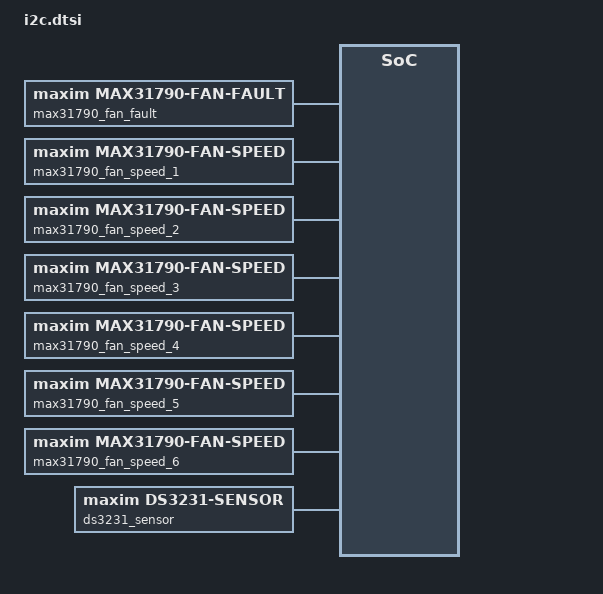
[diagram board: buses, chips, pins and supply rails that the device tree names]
/*
 * Copyright (c) 2020, Linaro Ltd.
 *
 * SPDX-License-Identifier: Apache-2.0
 *
 * Application overlay for i2c devices
 */

#include <zephyr/dt-bindings/sensor/lsm6dsv16x.h>
#include <zephyr/dt-bindings/sensor/lsm6dso.h>
#include <zephyr/dt-bindings/sensor/lsm6dso16is.h>
#include <zephyr/dt-bindings/sensor/lps22hh.h>
#include <zephyr/dt-bindings/sensor/lps2xdf.h>
#include <zephyr/dt-bindings/sensor/lis2ds12.h>
#include <zephyr/dt-bindings/sensor/lis2dw12.h>
#include <zephyr/dt-bindings/sensor/ism330dhcx.h>
#include <zephyr/dt-bindings/sensor/iis2dlpc.h>
#include <zephyr/dt-bindings/sensor/lis2dh.h>
#include <zephyr/dt-bindings/sensor/iis2iclx.h>
#include <zephyr/dt-bindings/sensor/lis2du12.h>
#include <zephyr/dt-bindings/sensor/lis2dux12.h>
#include <zephyr/dt-bindings/sensor/lis2de12.h>
#include <zephyr/dt-bindings/sensor/tmag5273.h>
#include <zephyr/dt-bindings/sensor/stts22h.h>
#include <zephyr/dt-bindings/sensor/ina226.h>
#include <zephyr/dt-bindings/sensor/apds9253.h>
#include <zephyr/dt-bindings/sensor/tmp11x.h>
#include <zephyr/dt-bindings/sensor/tmp114.h>

#define TEST_I2C_DEVICE_WITH_ADDR(label, node, addr, ...) \
	label: node@addr { \
		reg = <addr>; \
		__VA_ARGS__ \
	}

#define TEST_I2C_DEVICE(sensor, ...) \
	TEST_I2C_DEVICE_WITH_ADDR(test_i2c_##sensor, sensor, __COUNTER__, __VA_ARGS__)


TEST_I2C_DEVICE(adt7420,
	compatible = "adi,adt7420";
	int-gpios = <&test_gpio 0 0>;
);

TEST_I2C_DEVICE(adxl345,
	compatible = "adi,adxl345";
	int1-gpios = <&test_gpio 0 0>;
	fifo-watermark = <1>;
);

TEST_I2C_DEVICE(adxl372,
	compatible = "adi,adxl372";
	int1-gpios = <&test_gpio 0 0>;
);

TEST_I2C_DEVICE(ccs811,
	compatible = "ams,ccs811";
	wake-gpios = <&test_gpio 0 0>;
	reset-gpios = <&test_gpio 0 0>;
	irq-gpios = <&test_gpio 0 0>;
);

TEST_I2C_DEVICE(ens210,
	compatible = "ams,ens210";
);

TEST_I2C_DEVICE(iaqcore,
	compatible = "ams,iaqcore";
);

TEST_I2C_DEVICE(bme280,
	compatible = "bosch,bme280";
);

TEST_I2C_DEVICE(apds9960,
	compatible = "avago,apds9960";
	int-gpios = <&test_gpio 0 0>;
);

TEST_I2C_DEVICE(bma280,
	compatible = "bosch,bma280";
	int1-gpios = <&test_gpio 0 0>;
	/* is-bmc150; */
);

TEST_I2C_DEVICE(bmc150_magn,
	compatible = "bosch,bmc150_magn";
	drdy-gpios = <&test_gpio 0 0>;
);

TEST_I2C_DEVICE(ak8975,
	compatible = "asahi-kasei,ak8975";
);

TEST_I2C_DEVICE(bme680,
	compatible = "bosch,bme680";
);

TEST_I2C_DEVICE(bmg160,
	compatible = "bosch,bmg160";
	int-gpios = <&test_gpio 0 0>;
);

TEST_I2C_DEVICE(bmm150,
	compatible = "bosch,bmm150";
	drdy-gpios = <&test_gpio 0 0>;
);

TEST_I2C_DEVICE(hmc5883l,
	compatible = "honeywell,hmc5883l";
	int-gpios = <&test_gpio 0 0>;
);

TEST_I2C_DEVICE(hp206c,
	compatible = "hoperf,hp206c";
);

TEST_I2C_DEVICE(th02,
	compatible = "hoperf,th02";
);

TEST_I2C_DEVICE(mpu6050,
	compatible = "invensense,mpu6050";
	int-gpios = <&test_gpio 0 0>;
);

TEST_I2C_DEVICE(mpu9250,
	compatible = "invensense,mpu9250";
	irq-gpios = <&test_gpio 0 0>;
	gyro-sr-div = <10>;
	gyro-dlpf = <5>;
	gyro-fs = <250>;
	accel-fs = <2>;
	accel-dlpf = "5.05";
);

TEST_I2C_DEVICE(ina219,
	compatible = "ti,ina219";
	brng = <0>;
	pg = <0>;
	sadc = <13>;
	badc = <13>;
	shunt-milliohm = <100>;
	lsb-microamp = <10>;
);

TEST_I2C_DEVICE(isl29035,
	compatible = "isil,isl29035";
	int-gpios = <&test_gpio 0 0>;
);

TEST_I2C_DEVICE(max30101,
	compatible = "maxim,max30101";
	acq-mode = "multi-led";
);

TEST_I2C_DEVICE(max44009,
	compatible = "maxim,max44009";
	int-gpios = <&test_gpio 0 0>;
);

TEST_I2C_DEVICE(ms5607,
	compatible = "meas,ms5607";
);

TEST_I2C_DEVICE(ms5837_02ba,
	compatible = "meas,ms5837-02ba";
	status = "okay";
);

TEST_I2C_DEVICE(jc42,
	compatible = "jedec,jc-42.4-temp";
	int-gpios = <&test_gpio 0 0>;
);

TEST_I2C_DEVICE(fxas21002,
	compatible = "nxp,fxas21002";
	int1-gpios = <&test_gpio 0 0>;
	int2-gpios = <&test_gpio 0 0>;
);

TEST_I2C_DEVICE(fxos8700,
	compatible = "nxp,fxos8700";
	reset-gpios = <&test_gpio 0 0>;
	int1-gpios = <&test_gpio 0 0>;
	int2-gpios = <&test_gpio 0 0>;
);

TEST_I2C_DEVICE(amg88xx,
	compatible = "panasonic,amg88xx";
	int-gpios = <&test_gpio 0 0>;
);

TEST_I2C_DEVICE(sx9500,
	compatible = "semtech,sx9500";
	int-gpios = <&test_gpio 0 0>;
);

TEST_I2C_DEVICE(sgp40,
	compatible = "sensirion,sgp40";
	enable-selftest;
);

TEST_I2C_DEVICE(sht3xd,
	compatible = "sensirion,sht3xd";
	alert-gpios = <&test_gpio 0 0>;
);

TEST_I2C_DEVICE(sht4xd,
	compatible = "sensirion,sht4x";
	repeatability = <2>;
);

TEST_I2C_DEVICE(shtc3,
	compatible = "sensirion,shtc3", "sensirion,shtcx";
	measure-mode = "normal";
	clock-stretching;
);

TEST_I2C_DEVICE(si7006,
	compatible = "silabs,si7006";
);

TEST_I2C_DEVICE(si7055,
	compatible = "silabs,si7055";
);

TEST_I2C_DEVICE(si7060,
	compatible = "silabs,si7060";
);

TEST_I2C_DEVICE(si7210,
	compatible = "silabs,si7210";
);

TEST_I2C_DEVICE(hts221,
	compatible = "st,hts221";
	drdy-gpios = <&test_gpio 0 0>;
);

TEST_I2C_DEVICE(iis2dlpc,
	compatible = "st,iis2dlpc";
	drdy-gpios = <&test_gpio 0 0>;
	tap-mode = <IIS2DLPC_DT_SINGLE_DOUBLE_TAP>;
	power-mode = <IIS2DLPC_DT_HP_MODE>;
);

TEST_I2C_DEVICE(iis2mdc,
	compatible = "st,iis2mdc";
	drdy-gpios = <&test_gpio 0 0>;
);

TEST_I2C_DEVICE(ism330dhcx,
	compatible = "st,ism330dhcx";
	drdy-gpios = <&test_gpio 0 0>;
	accel-odr = <ISM330DHCX_DT_ODR_104Hz>;
	gyro-odr = <ISM330DHCX_DT_ODR_104Hz>;
);

TEST_I2C_DEVICE(lis2dh,
	compatible = "st,lis2dh";
	irq-gpios = <&test_gpio 0 0>;
	/* disconnect-sdo-sa0-pull-up; */
	int1-gpio-config = <LIS2DH_DT_GPIO_INT_LEVEL_LOW>;
	int2-gpio-config = <LIS2DH_DT_GPIO_INT_LEVEL_LOW>;
	anym-mode = <LIS2DH_DT_ANYM_6D_POSITION>;
);

TEST_I2C_DEVICE(lis2dh12,
	compatible = "st,lis2dh12";
	irq-gpios = <&test_gpio 0 0>;
	status = "disabled";
);

TEST_I2C_DEVICE(lis2ds12,
	compatible = "st,lis2ds12";
	irq-gpios = <&test_gpio 0 0>;
	power-mode = <LIS2DS12_DT_LOW_POWER>;
	odr = <LIS2DS12_DT_ODR_12Hz5>;
);

TEST_I2C_DEVICE(lis2dw12,
	compatible = "st,lis2dw12";
	irq-gpios = <&test_gpio 0 0>;
	wakeup-duration = <LIS2DW12_DT_WAKEUP_4_ODR>;
	ff-threshold = <LIS2DW12_DT_FF_THRESHOLD_500_mg>;
	tap-mode = <LIS2DW12_DT_SINGLE_DOUBLE_TAP>;
	power-mode = <LIS2DW12_DT_HP_MODE>;
	bw-filt = <LIS2DW12_DT_FILTER_BW_ODR_DIV_2>;
);

TEST_I2C_DEVICE(lis2mdl,
	compatible = "st,lis2mdl";
	irq-gpios = <&test_gpio 0 0>;
);

TEST_I2C_DEVICE(lis3dh,
	compatible = "st,lis3dh";
	irq-gpios = <&test_gpio 0 0>;
	status = "disabled";
);

TEST_I2C_DEVICE(lis3mdl_magn,
	compatible = "st,lis3mdl-magn";
	irq-gpios = <&test_gpio 0 0>;
);

TEST_I2C_DEVICE(lps22hb_press,
	compatible = "st,lps22hb-press";
);

TEST_I2C_DEVICE(lps22hh,
	compatible = "st,lps22hh";
	drdy-gpios = <&test_gpio 0 0>;
	odr = <LPS22HH_DT_ODR_200HZ>;
);

TEST_I2C_DEVICE(lps25hb_press,
	compatible = "st,lps25hb-press";
);

TEST_I2C_DEVICE(lsm303agr_accel,
	compatible = "st,lsm303agr-accel";
	irq-gpios = <&test_gpio 0 0>;
	/* disconnect-sdo-sa0-pull-up; */
	status = "disabled";
);

TEST_I2C_DEVICE(lsm303dlhc_accel,
	compatible = "st,lsm303dlhc-accel";
	irq-gpios = <&test_gpio 0 0>;
	/* disconnect-sdo-sa0-pull-up; */
	status = "disabled";
);

TEST_I2C_DEVICE(lsm303dlhc_magn,
	compatible = "st,lsm303dlhc-magn";
);

TEST_I2C_DEVICE(lsm6ds0,
	compatible = "st,lsm6ds0";
);

TEST_I2C_DEVICE(lsm6dsl,
	compatible = "st,lsm6dsl";
	irq-gpios = <&test_gpio 0 0>;
);

TEST_I2C_DEVICE(lsm6dso,
	compatible = "st,lsm6dso";
	irq-gpios = <&test_gpio 0 0>;
	accel-pm = <LSM6DSO_DT_XL_ULP_MODE>;
	accel-range = <LSM6DSO_DT_FS_8G>;
	accel-odr = <LSM6DSO_DT_ODR_1Hz6>;
	gyro-pm = <LSM6DSO_DT_GY_NORMAL_MODE>;
	gyro-range = <LSM6DSO_DT_FS_2000DPS>;
	gyro-odr = <LSM6DSO_DT_ODR_6667Hz>;
);

TEST_I2C_DEVICE(lsm9ds0_gyro,
	compatible = "st,lsm9ds0-gyro";
	irq-gpios = <&test_gpio 0 0>;
);

TEST_I2C_DEVICE(lsm9ds0_mfd,
	compatible = "st,lsm9ds0-mfd";
	irq-gpios = <&test_gpio 0 0>;
);

TEST_I2C_DEVICE(stts751,
	compatible = "st,stts751";
	drdy-gpios = <&test_gpio 0 0>;
);

TEST_I2C_DEVICE(vl53l0x,
	compatible = "st,vl53l0x";
	xshut-gpios = <&test_gpio 0 0>;
);

TEST_I2C_DEVICE(hdc,
	compatible = "ti,hdc";
	drdy-gpios = <&test_gpio 0 0>;
);

TEST_I2C_DEVICE(hdc2010,
	compatible = "ti,hdc2010";
);

TEST_I2C_DEVICE(hdc2021,
	compatible = "ti,hdc2021";
);

TEST_I2C_DEVICE(hdc2022,
	compatible = "ti,hdc2022";
);

TEST_I2C_DEVICE(hdc2080,
	compatible = "ti,hdc2080";
);

TEST_I2C_DEVICE(opt3001,
	compatible = "ti,opt3001";
);

TEST_I2C_DEVICE(tmp007,
	compatible = "ti,tmp007";
	int-gpios = <&test_gpio 0 0>;
);

TEST_I2C_DEVICE(tmp108,
	compatible = "ti,tmp108";
	alert-gpios = <&test_gpio 0 0>;
);

TEST_I2C_DEVICE(tmp112,
	compatible = "ti,tmp112";
);

TEST_I2C_DEVICE(tmp11x,
	compatible = "ti,tmp11x";
	odr = <TMP11X_DT_ODR_125_MS>;
	oversampling = <TMP11X_DT_OVERSAMPLING_32>;
	alert-gpios = <&test_gpio 0 0>;
);

TEST_I2C_DEVICE(bq274xx,
	compatible = "ti,bq274xx";
	design-voltage = <3700>;
	design-capacity = <1800>;
	taper-current = <45>;
	terminate-voltage = <3000>;
	int-gpios = <&test_gpio 0 0>;
);

TEST_I2C_DEVICE(mpr,
	compatible = "honeywell,mpr";
);

TEST_I2C_DEVICE(dps310,
	compatible = "infineon,dps310";
);

TEST_I2C_DEVICE(iis2dh,
	compatible = "st,iis2dh";
	drdy-gpios = <&test_gpio 0 0>;
);

TEST_I2C_DEVICE(iis2iclx,
	compatible = "st,iis2iclx";
	drdy-gpios = <&test_gpio 0 0>;
	int-pin = <1>;
	range = <IIS2ICLX_DT_FS_2G>;
	odr = <IIS2ICLX_DT_ODR_833Hz>;
);

TEST_I2C_DEVICE(itds_2533020201601,
	compatible = "we,wsen-itds-2533020201601";
	events-interrupt-gpios = <&test_gpio 0 0>;
	drdy-interrupt-gpios = <&test_gpio 0 0>;
	odr = "400";
	tap-threshold = <0>, <0>, <6>;
	tap-latency = <5>;
	tap-shock = <2>;
	tap-quiet = <1>;
	tap-mode = <1>;
	freefall-duration = <6>;
	freefall-threshold = <10>;
	delta-duration = <1>;
	delta-threshold = <4>;
	op-mode = "high-perf";
	power-mode = "normal";
);

TEST_I2C_DEVICE(max17055,
	compatible = "maxim,max17055";
	design-capacity = <1500>;
	design-voltage = <3860>;
	desired-charging-current = <2000>;
	desired-voltage = <4400>;
	i-chg-term = <100>;
	rsense-mohms = <5>;
	v-empty = <3300>;
);

TEST_I2C_DEVICE(max17262,
	compatible = "maxim,max17262";
	design-voltage = <3600>;
	desired-voltage = <3600>;
	desired-charging-current = <2000>;
	design-cap = <17000>;
	empty-voltage = <3300>;
	recovery-voltage = <3880>;
	charge-voltage = <3600>;
);

TEST_I2C_DEVICE(vcnl4040,
	compatible = "vishay,vcnl4040";
	int-gpios = <&test_gpio 0 0>;
);

TEST_I2C_DEVICE(bmi160,
	compatible = "bosch,bmi160";
	int-gpios = <&test_gpio 0 0>;
);

TEST_I2C_DEVICE(bmi270,
	compatible = "bosch,bmi270";
	irq-gpios = <&test_gpio 0 0>;
);

TEST_I2C_DEVICE(fdc2x1x,
	compatible = "ti,fdc2x1x";
	intb-gpios = <&test_gpio 0 0>;
	sd-gpios = <&test_gpio 0 0>;
	deglitch = <5>;
	fref = <43360>;
	channel_0 {
		rcount = <7499>;
		settlecount = <48>;
		fref-divider = <1>;
		idrive = <10>;
		fin-sel = <2>;
		inductance = <18>;
	};
);

TEST_I2C_DEVICE(bmp388,
	compatible = "bosch,bmp388";
	int-gpios = <&test_gpio 0 0>;
);

TEST_I2C_DEVICE(lm75,
	compatible = "lm75";
	int-gpios = <&test_gpio 0 0>;
);

TEST_I2C_DEVICE(ina230,
	compatible = "ti,ina230";
	current-lsb-microamps = <1000>;
	rshunt-micro-ohms = <1000>;
	mask = <0>;
	alert-limit = <0>;
	alert-gpios = <&test_gpio 0 0>;
);

TEST_I2C_DEVICE(lm77,
	compatible = "lm77";
	int-gpios = <&test_gpio 0 0>;
);

TEST_I2C_DEVICE(ina231,
	compatible = "ti,ina230";
	current-lsb-microamps = <1000>;
	rshunt-micro-ohms = <1000>;
	mask = <0>;
	alert-limit = <0>;
	alert-gpios = <&test_gpio 0 0>;
);

TEST_I2C_DEVICE(ina237,
	compatible = "ti,ina237";
	current-lsb-microamps = <1000>;
	rshunt-micro-ohms = <1000>;
	alert-config = <0>;
	alert-gpios = <&test_gpio 0 0>;
);

TEST_I2C_DEVICE(max31875,
	compatible = "maxim,max31875";
);

TEST_I2C_DEVICE(icp101xx,
	compatible = "invensense,icp101xx";
	mode = "normal";
);

TEST_I2C_DEVICE(as5600,
	compatible = "ams,as5600";
);

TEST_I2C_DEVICE(bh1750,
	compatible = "rohm,bh1750";
);

TEST_I2C_DEVICE(akm09918c,
	compatible = "asahi-kasei,akm09918c";
);

TEST_I2C_DEVICE(wsen_tids_2521020222501,
	compatible = "we,wsen-tids-2521020222501";
	interrupt-gpios = <&test_gpio 0 0>;
	odr = <25>;
);

TEST_I2C_DEVICE(vl53l1x,
	compatible = "st,vl53l1x";
	int-gpios = <&test_gpio 0 0>;
	xshut-gpios = <&test_gpio 0 0>;
);

TEST_I2C_DEVICE(tmd2620,
	compatible = "ams,tmd2620";
	int-gpios = <&test_gpio 0 0>;
	proximity-gain = <4>;
	proximity-pulse-length = <16>;
	proximity-pulse-count = <15>;
	proximity-high-threshold = <255>;
	proximity-low-threshold = <0>;
	proximity-led-drive-strength = <4>;
	proximity-interrupt-filter = <0>;
	wait-time-factor = <0>;
);

TEST_I2C_DEVICE(wsen_pads_2511020213301,
	compatible = "we,wsen-pads-2511020213301";
	interrupt-gpios = <&test_gpio 0 0>;
	odr = <10>;
);

TEST_I2C_DEVICE(s11059,
	compatible = "hamamatsu,s11059";
	integration-time = <546000>;
);

TEST_I2C_DEVICE(wsen_pdus_25131308XXXXX,
	compatible = "we,wsen-pdus-25131308XXXXX";
	sensor-type = <4>;
);

TEST_I2C_DEVICE(veml7700,
	compatible = "vishay,veml7700";
	psm-mode = <0x03>;
);

TEST_I2C_DEVICE(ina3221,
	compatible = "ti,ina3221";
	shunt-resistors = <1000 1000 1000>;
	enable-channel = <1 0 0>;
	conv-time-bus = <7>;
	conv-time-shunt = <7>;
	avg-mode = <2>;
);

TEST_I2C_DEVICE(lsm6dso16is,
	compatible = "st,lsm6dso16is";
	irq-gpios = <&test_gpio 0 0>;
	accel-range = <LSM6DSO16IS_DT_FS_8G>;
	accel-odr = <LSM6DSO16IS_DT_ODR_104Hz_LP>;
	gyro-range = <LSM6DSO16IS_DT_FS_2000DPS>;
	gyro-odr = <LSM6DSO16IS_DT_ODR_104Hz_LP>;
);

TEST_I2C_DEVICE(lsm6dsv16x,
	compatible = "st,lsm6dsv16x";
	int1-gpios = <&test_gpio 0 0>;
	int2-gpios = <&test_gpio 0 0>;
	accel-range = <LSM6DSV16X_DT_FS_8G>;
	accel-odr = <LSM6DSV16X_DT_ODR_AT_60Hz>;
	gyro-range = <LSM6DSV16X_DT_FS_2000DPS>;
	gyro-odr = <LSM6DSV16X_DT_ODR_AT_60Hz>;
);

TEST_I2C_DEVICE(mcp9600,
	compatible = "microchip,mcp9600";
);

TEST_I2C_DEVICE(tcs3400,
	compatible = "ams,tcs3400";
	int-gpios = <&test_gpio 0 0>;
);

TEST_I2C_DEVICE(tcn75a,
	compatible = "microchip,tcn75a";
	alert-gpios = <&test_gpio 0 0>;
);

TEST_I2C_DEVICE(bmi08x_accel,
	compatible = "bosch,bmi08x-accel";
	int-gpios = <&test_gpio 0 0>;
	int1-map-io = <0x01>;
	int2-map-io = <0x00>;
	int1-conf-io = <0x0A>;
	int2-conf-io = <0x17>;
	accel-hz = "800";
	accel-fs = <4>;
	fifo-watermark = <1>;
);

TEST_I2C_DEVICE(bmi08x_gyro,
	compatible = "bosch,bmi08x-gyro";
	int-gpios = <&test_gpio 0 0>;
	int3-4-map-io = <0x01>;
	int3-4-conf-io = <0x01>;
	gyro-hz = "1000_116";
	gyro-fs = <1000>;
	fifo-watermark = <1>;
);

TEST_I2C_DEVICE(ist8310,
	compatible = "isentek,ist8310";
	status = "okay";
);

TEST_I2C_DEVICE(f75303,
	compatible = "fintek,f75303";
);

TEST_I2C_DEVICE(tsl2540,
	compatible = "ams,tsl2540";
	int-gpios = <&test_gpio 0 0>;
);

TEST_I2C_DEVICE(adltc2990,
	compatible = "adi,adltc2990";
	status = "okay";
	measurement-mode = <7 3>;
	pins-v1-v2-current-resistor = <1>;
	pin-v1-voltage-divider-resistors = <100 10>;
	pin-v2-voltage-divider-resistors = <100 10>;
	pin-v3-voltage-divider-resistors = <100 100>;
	pin-v4-voltage-divider-resistors = <0 1>;
);

TEST_I2C_DEVICE(hm330x,
	compatible = "seeed,hm330x";
	status = "okay";
);

TEST_I2C_DEVICE(amd_sb_tsi,
	compatible = "amd,sb-tsi";
);

TEST_I2C_DEVICE(mc3419,
	compatible = "memsic,mc3419";
	int-gpios = <&test_gpio 0 0>;
);

TEST_I2C_DEVICE(ltrf216a0,
	compatible = "liteon,ltrf216a";
);

TEST_I2C_DEVICE(adxl367,
	compatible = "adi,adxl367";
	odr = <4>;
	int1-gpios = <&test_gpio 0 0>;
);

TEST_I2C_DEVICE(tsl2561,
	compatible = "ams,tsl2561";
);

TEST_I2C_DEVICE(lps22df,
	compatible = "st,lps22df";
	drdy-gpios = <&test_gpio 0 0>;
	status = "okay";
	odr = <LPS2xDF_DT_ODR_10HZ>;
	lpf = <LPS2xDF_DT_LP_FILTER_ODR_4>;
	avg = <LPS2xDF_DT_AVG_128_SAMPLES>;
);

TEST_I2C_DEVICE(hs300x,
	compatible = "renesas,hs300x";
);

TEST_I2C_DEVICE(lps28dfw,
	compatible = "st,lps28dfw";
	drdy-gpios = <&test_gpio 0 0>;
	status = "okay";
	odr = <LPS2xDF_DT_ODR_10HZ>;
	lpf = <LPS2xDF_DT_LP_FILTER_ODR_4>;
	avg = <LPS2xDF_DT_AVG_128_SAMPLES>;
	fs = <LPS28DFW_DT_FS_MODE_1_1260>;
);

TEST_I2C_DEVICE(lis2du12,
	compatible = "st,lis2du12";
	int1-gpios = <&test_gpio 0 0>;
	int2-gpios = <&test_gpio 0 0>;
	accel-range = <LIS2DU12_DT_FS_16G>;
	accel-odr = <LIS2DU12_DT_ODR_AT_800Hz>;
);

TEST_I2C_DEVICE(bma4xx,
	compatible = "bosch,bma4xx";
);

TEST_I2C_DEVICE(ags10,
	compatible = "aosong,ags10";
);

TEST_I2C_DEVICE(bmp581,
	compatible = "bosch,bmp581";
	int-gpios = <&test_gpio 0 0>;
);

TEST_I2C_DEVICE(lis2de12,
	compatible = "st,lis2de12";
	int1-gpios = <&test_gpio 0 0>;
	int2-gpios = <&test_gpio 0 0>;
	accel-range = <LIS2DE12_DT_FS_16G>;
	accel-odr = <LIS2DE12_DT_ODR_AT_100Hz>;
);

TEST_I2C_DEVICE(vishay_vcnl36825t,
	compatible = "vishay,vcnl36825t";

	proximity-it = "1";
	multi-pulse = <8>;

	low-power;

	int-gpios = <&test_gpio 0 0>;
);

TEST_I2C_DEVICE(tmag5273,
	compatible = "ti,tmag5273";
	status = "okay";
	int-gpios = <&test_gpio 15 1>;

	operation-mode = <TMAG5273_DT_OPER_MODE_CONTINUOUS>;
	angle-magnitude-axis = <TMAG5273_DT_ANGLE_MAG_XY>;
);

TEST_I2C_DEVICE(ens160,
	compatible = "sciosense,ens160";
	int-gpios = <&test_gpio 0 0>;
);

TEST_I2C_DEVICE(tsl2591,
	compatible = "ams,tsl2591";
	int-gpios = <&test_gpio 0 0>;
);

TEST_I2C_DEVICE(max31790,
	compatible = "maxim,max31790";
	status = "okay";

	max31790_fan_fault: max31790_fan_fault {
		compatible = "maxim,max31790-fan-fault";
		status = "okay";
	};

	max31790_fan_speed_1: max31790_fan_speed_1 {
		compatible = "maxim,max31790-fan-speed";
		status = "okay";
		channel = <1>;
	};

	max31790_fan_speed_2: max31790_fan_speed_2 {
		compatible = "maxim,max31790-fan-speed";
		status = "okay";
		channel = <2>;
	};

	max31790_fan_speed_3: max31790_fan_speed_3 {
		compatible = "maxim,max31790-fan-speed";
		status = "okay";
		channel = <3>;
	};

	max31790_fan_speed_4: max31790_fan_speed_4 {
		compatible = "maxim,max31790-fan-speed";
		status = "okay";
		channel = <4>;
	};

	max31790_fan_speed_5: max31790_fan_speed_5 {
		compatible = "maxim,max31790-fan-speed";
		status = "okay";
		channel = <5>;
	};

	max31790_fan_speed_6: max31790_fan_speed_6 {
		compatible = "maxim,max31790-fan-speed";
		status = "okay";
		channel = <6>;
	};
);

TEST_I2C_DEVICE(stts22h,
	compatible = "st,stts22h";
	int-gpios = <&test_gpio 0 0>;
	sampling-rate = <STTS22H_100Hz>;
);

TEST_I2C_DEVICE(dht20,
	compatible = "aosong,dht20";
	status = "okay";
);

TEST_I2C_DEVICE(aht20,
	compatible = "aosong,aht20";
	status = "okay";
);

TEST_I2C_DEVICE(am2301b,
	compatible = "aosong,am2301b";
);

TEST_I2C_DEVICE(lis2dux12,
	compatible = "st,lis2dux12";
	int1-gpios = <&test_gpio 0 0>;
	int2-gpios = <&test_gpio 0 0>;
	range = <LIS2DUX12_DT_FS_16G>;
	odr = <LIS2DUX12_DT_ODR_100Hz>;
	power-mode = <LIS2DUX12_OPER_MODE_HIGH_PERFORMANCE>;
	status = "okay";
);

TEST_I2C_DEVICE(iis328dq,
	compatible = "st,iis328dq";
	status = "okay";
	int2-gpios = <&test_gpio 0 0>;
	threshold-int-pad = <2>;
);

TEST_I2C_DEVICE(nct75,
	compatible = "onnn,nct75";
	status = "okay";
);

TEST_I2C_DEVICE(tmp114,
	compatible = "ti,tmp114";
	odr = <TMP114_DT_ODR_250_MS>;
);

TEST_I2C_DEVICE(ina226,
	compatible = "ti,ina226";
	current-lsb-microamps = <5000>;
	rshunt-micro-ohms = <500>;
);

TEST_I2C_DEVICE(shtc1,
	compatible = "sensirion,shtc1", "sensirion,shtcx";
	measure-mode = "low-power";
	clock-stretching;
);

TEST_I2C_DEVICE(lm95234,
	compatible = "national,lm95234";
	status = "okay";
);

TEST_I2C_DEVICE(sht21,
	compatible = "sensirion,sht21";
);

TEST_I2C_DEVICE(lsm9ds1,
	compatible = "st,lsm9ds1";
);

TEST_I2C_DEVICE(icm42670p,
	compatible = "invensense,icm42670p";
	int-gpios = <&test_gpio 0 0>;
	accel-hz = <800>;
	accel-fs = <16>;
	gyro-hz = <800>;
	gyro-fs = <2000>;
);

TEST_I2C_DEVICE(fxls8974,
	compatible = "nxp,fxls8974";
	reset-gpios = <&test_gpio 0 0>;
	int1-gpios = <&test_gpio 0 0>;
	int2-gpios = <&test_gpio 0 0>;
);

TEST_I2C_DEVICE(bmp180,
	compatible = "bosch,bmp180";
	osr-press = <0x01>;
);

TEST_I2C_DEVICE(apds9253,
	compatible = "avago,apds9253";
	int-gpios = <&test_gpio 0 0>;
	gain = <APDS9253_GAIN_RANGE_1>;
	rate = <APDS9253_MEASUREMENT_RATE_50MS>;
	resolution = <APDS9253_RESOLUTION_16BIT_25MS>;
);

TEST_I2C_DEVICE(mmc56x3,
	compatible = "memsic,mmc56x3";
	magn-odr = <0>;
	auto-self-reset;
);

TEST_I2C_DEVICE(tmp1075,
	compatible = "ti,tmp1075";
	alert-gpios = <&test_gpio 0 0>;
	conversion-rate = <220000>;
	lower-threshold = <27>;
	upper-threshold = <28>;
	consecutive-fault-measurements = <4>;
	interrupt-mode;
);

TEST_I2C_DEVICE(bmp390,
	compatible = "bosch,bmp390";
	int-gpios = <&test_gpio 0 0>;
	osr-press = <0x01>;
	odr = "12.5";
	osr-press = <8>;
	osr-temp = <1>;
	iir-filter = <3>;
);

TEST_I2C_DEVICE(apds9306,
	compatible = "avago,apds9306";
	status = "okay";
	gain = <1>;
	resolution = <13>;
	measurement-period = <2000>;
);

TEST_I2C_DEVICE(wsen_hids_2525020210002,
	compatible = "we,wsen-hids-2525020210002";
	precision = "high";
);

TEST_I2C_DEVICE(ilps22qs,
	compatible = "st,ilps22qs";
	status = "okay";
	odr = <LPS2xDF_DT_ODR_10HZ>;
	lpf = <LPS2xDF_DT_LP_FILTER_ODR_4>;
	avg = <LPS2xDF_DT_AVG_128_SAMPLES>;
	fs = <ILPS22QS_DT_FS_MODE_1_1260>;
);

TEST_I2C_DEVICE(sts4x,
	compatible = "sensirion,sts4x";
	repeatability = <2>;
);

TEST_I2C_DEVICE(scd41,
	compatible = "sensirion,scd41";
	mode = <0>;
);

TEST_I2C_DEVICE(npm2100,
	compatible = "nordic,npm2100";

	vbat {
		compatible = "nordic,npm2100-vbat";
	};
);

TEST_I2C_DEVICE(mlx90394,
	compatible = "melexis,mlx90394";
	status = "okay";
);

TEST_I2C_DEVICE(scd40,
	compatible = "sensirion,scd40";
);

TEST_I2C_DEVICE(ina236,
	compatible = "ti,ina236";
	current-lsb-microamps = <1000>;
	rshunt-micro-ohms = <1000>;
	mask = <0>;
	alert-limit = <0>;
	alert-gpios = <&test_gpio 0 0>;
);

TEST_I2C_DEVICE(as6212,
	compatible = "ams,as6212";
);

TEST_I2C_DEVICE(p3t1755,
	compatible = "nxp,p3t1755";
);

TEST_I2C_DEVICE(lsm6dso32,
	compatible = "st,lsm6dso32";
	irq-gpios = <&test_gpio 0 0>;
	accel-pm = <LSM6DSO_DT_XL_ULP_MODE>;
	accel-range = <LSM6DSO_DT_FS_8G>;
	accel-odr = <LSM6DSO_DT_ODR_1Hz6>;
	gyro-pm = <LSM6DSO_DT_GY_NORMAL_MODE>;
	gyro-range = <LSM6DSO_DT_FS_2000DPS>;
	gyro-odr = <LSM6DSO_DT_ODR_6667Hz>;
);

TEST_I2C_DEVICE(hs400x,
	compatible = "renesas,hs400x";
);

TEST_I2C_DEVICE(lis2duxs12,
	compatible = "st,lis2duxs12";
	int1-gpios = <&test_gpio 0 0>;
	int2-gpios = <&test_gpio 0 0>;
	range = <LIS2DUX12_DT_FS_16G>;
	odr = <LIS2DUX12_DT_ODR_100Hz>;
	power-mode = <LIS2DUX12_OPER_MODE_HIGH_PERFORMANCE>;
	status = "okay";
);

TEST_I2C_DEVICE(tmag3001,
	compatible = "ti,tmag3001";
	status = "okay";
	int-gpios = <&test_gpio 15 1>;
	operation-mode = <TMAG5273_DT_OPER_MODE_CONTINUOUS>;
	angle-magnitude-axis = <TMAG5273_DT_ANGLE_MAG_XY>;
);

TEST_I2C_DEVICE(tmp435,
	compatible = "ti,tmp435";
	external-channel;
	resistance-correction;
	beta-compensation = <0x0f>;
);

TEST_I2C_DEVICE(xbr818,
	compatible = "phosense,xbr818";
	int-gpios = <&test_gpio 0 0>;
	i2c-en-gpios = <&test_gpio 0 0>;
);

TEST_I2C_DEVICE(veml6031,
	compatible = "vishay,veml6031";
);

TEST_I2C_DEVICE(bmm350,
	compatible = "bosch,bmm350";
	drdy-gpios = <&test_gpio 0 0>;
);

TEST_I2C_DEVICE(ltr329,
	compatible = "liteon,ltr329";
);

TEST_I2C_DEVICE(ms5837_30ba,
	compatible = "meas,ms5837-30ba";
	status = "okay";
);

TEST_I2C_DEVICE(icp201xx,
	compatible = "invensense,icp201xx";
	int-gpios = <&test_gpio 0 0>;
	op-mode = "mode0";
	drive-strength = "current_12mA_1_8V";
);

TEST_I2C_DEVICE(paj7620,
	compatible = "pixart,paj7620";
	int-gpios = <&test_gpio 0 0>;
);

TEST_I2C_DEVICE(icm45686,
	compatible = "invensense,icm45686";
	int-gpios = <&test_gpio 0 0>;
);

TEST_I2C_DEVICE(rm3100,
	compatible = "pni,rm3100";
	int-gpios = <&test_gpio 0 0>;
);

TEST_I2C_DEVICE(bh1790,
	compatible = "rohm,bh1790";
);

TEST_I2C_DEVICE(bh1730,
	compatible = "rohm,bh1730";
);

TEST_I2C_DEVICE(npm1300,
	compatible = "nordic,npm1300";

	charger {
		compatible = "nordic,npm1300-charger";
		vbus-limit-microamp = <1000000>;
		thermistor-ohms = <10000>;
		thermistor-beta = <3380>;
		term-microvolt = <4150000>;
		current-microamp = <150000>;
		dischg-limit-microamp = <1000000>;
	};
);

TEST_I2C_DEVICE(npm1304,
	compatible = "nordic,npm1304";

	charger {
		compatible = "nordic,npm1304-charger";
		vbus-limit-microamp = <1000000>;
		thermistor-ohms = <10000>;
		thermistor-beta = <3380>;
		term-microvolt = <4150000>;
		current-microamp = <10000>;
	};
);

TEST_I2C_DEVICE(ds3231,
	compatible = "maxim,ds3231-mfd";

	test_i2c_ds3231_sensor: ds3231_sensor {
		compatible = "maxim,ds3231-sensor";
	};
);

TEST_I2C_DEVICE(adxl366,
	compatible = "adi,adxl366";
	int1-gpios = <&test_gpio 0 0>;
	odr = <4>;
	fifo-mode = <0>;
);

TEST_I2C_DEVICE(lsm9ds1_mag,
	compatible = "st,lsm9ds1_mag";
);

TEST_I2C_DEVICE(mb7040,
	compatible = "maxbotix,mb7040";
	status-gpios = <&test_gpio 0 0>;
);

TEST_I2C_DEVICE(wsen_isds_2536030320001,
	compatible = "we,wsen-isds-2536030320001";
	accel-odr = "416";
	gyro-odr = "416";
	tap-threshold = <9>;
	tap-latency = <5>;
	tap-shock = <2>;
	tap-quiet = <1>;
	tap-mode = <1>;
	tap-axis-enable = <0 0 1>;
	events-interrupt-gpios = <&test_gpio 0 0>;
	drdy-interrupt-gpios = <&test_gpio 0 0>;
);

TEST_I2C_DEVICE(ina7xx,
	compatible = "ti,ina7xx";
	inatype = <2>;
	convdly = <0x80>;
	mode = <0xf>;
	vbusct = <5>;
	vsenct = <5>;
	tct = <5>;
	avg = <3>;
);

TEST_I2C_DEVICE(als31300,
	compatible = "allegro,als31300";
);

TEST_I2C_DEVICE(hdc302x,
	compatible = "ti,hdc302x";
	int-gpios = <&test_gpio 0 0>;
);

TEST_I2C_DEVICE(veml6046,
	compatible = "vishay,veml6046";
);

TEST_I2C_DEVICE(wsen_pdms_25131308XXX05,
	compatible = "we,wsen-pdms-25131308XXX05";
	sensor-type = <4>;
);
